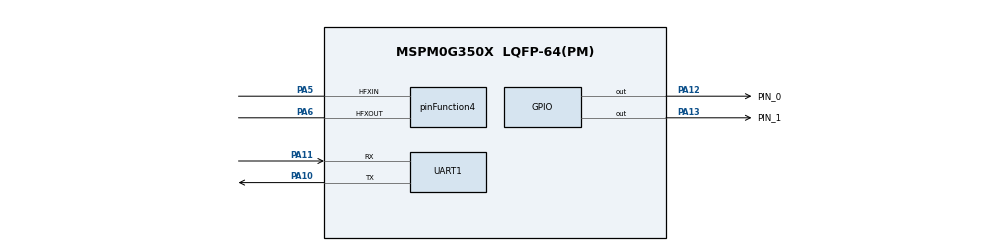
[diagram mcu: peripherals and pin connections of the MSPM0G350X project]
/**
 * @cliArgs --device "MSPM0G350X" --part "Default" --package "LQFP-64(PM)" --product "mspm0_sdk@2.10.00.04"
 * @versions {"tool":"1.26.2+4477"}
 */

/**
 * Import the modules used in this configuration.
 */
const ADC12  = scripting.addModule("/ti/driverlib/ADC12", {}, false);
const ADC121 = ADC12.addInstance();
const GPIO   = scripting.addModule("/ti/driverlib/GPIO", {}, false);
const GPIO1  = GPIO.addInstance();
const SYSCTL = scripting.addModule("/ti/driverlib/SYSCTL");
const TIMER  = scripting.addModule("/ti/driverlib/TIMER", {}, false);
const TIMER1 = TIMER.addInstance();
const UART   = scripting.addModule("/ti/driverlib/UART", {}, false);
const UART1  = UART.addInstance();

/**
 * Write custom configuration values to the imported modules.
 */
const mux4       = system.clockTree["EXHFMUX"];
mux4.inputSelect = "EXHFMUX_XTAL";

const mux8       = system.clockTree["HSCLKMUX"];
mux8.inputSelect = "HSCLKMUX_HFCLK";

const pinFunction4                        = system.clockTree["HFXT"];
pinFunction4.enable                       = true;
pinFunction4.HFCLKMonitor                 = true;
pinFunction4.HFXTStartup                  = 10;
pinFunction4.inputFreq                    = 40;
pinFunction4.peripheral.hfxInPin.$assign  = "PA5";
pinFunction4.peripheral.hfxOutPin.$assign = "PA6";

ADC121.$name                          = "ADC12_0";
ADC121.repeatMode                     = true;
ADC121.trigSrc                        = "DL_ADC12_TRIG_SRC_EVENT";
ADC121.sampClkSrc                     = "DL_ADC12_CLOCK_ULPCLK";
ADC121.subChanID                      = 1;
ADC121.adcMem0chansel                 = "DL_ADC12_INPUT_CHAN_2";
ADC121.adcMem0trig                    = "DL_ADC12_TRIGGER_MODE_TRIGGER_NEXT";
ADC121.sampleTime0                    = "62.5 ns";
ADC121.powerDownMode                  = "DL_ADC12_POWER_DOWN_MODE_MANUAL";
ADC121.configureDMA                   = true;
ADC121.sampCnt                        = 1;
ADC121.enabledDMATriggers             = ["DL_ADC12_DMA_MEM0_RESULT_LOADED"];
ADC121.enabledInterrupts              = ["DL_ADC12_INTERRUPT_DMA_DONE"];
ADC121.peripheral.$assign             = "ADC0";
ADC121.peripheral.adcPin2.$assign     = "PA25";
ADC121.adcPin2Config.$name            = "ti_driverlib_gpio_GPIOPinGeneric0";
ADC121.DMA_CHANNEL.$name              = "DMA_CH0";
ADC121.DMA_CHANNEL.addressMode        = "f2b";
ADC121.DMA_CHANNEL.srcLength          = "HALF_WORD";
ADC121.DMA_CHANNEL.dstLength          = "HALF_WORD";
ADC121.DMA_CHANNEL.peripheral.$assign = "DMA_CH0";

const Board = scripting.addModule("/ti/driverlib/Board", {}, false);

GPIO1.$name                         = "GPIO_GRP_0";
GPIO1.port                          = "PORTA";
GPIO1.associatedPins.create(2);
GPIO1.associatedPins[0].$name       = "PIN_0";
GPIO1.associatedPins[0].pin.$assign = "PA12";
GPIO1.associatedPins[1].$name       = "PIN_1";
GPIO1.associatedPins[1].pin.$assign = "PA13";

SYSCTL.forceDefaultClkConfig = true;
SYSCTL.validateClkStatus     = true;
SYSCTL.clockTreeEn           = true;

TIMER1.$name                       = "SAMPLE_TIMER";
TIMER1.timerMode                   = "PERIODIC";
TIMER1.event1PublisherChannel      = 1;
TIMER1.event1ControllerInterruptEn = ["ZERO_EVENT"];
TIMER1.timerPeriod                 = "400ns";
TIMER1.peripheral.$assign          = "TIMG0";

UART1.$name                       = "UART_0";
UART1.targetBaudRate              = 115200;
UART1.enabledInterrupts           = ["DMA_DONE_RX"];
UART1.enabledDMARXTriggers        = "DL_UART_DMA_INTERRUPT_RX";
UART1.peripheral.rxPin.$assign    = "PA11";
UART1.peripheral.txPin.$assign    = "PA10";
UART1.txPinConfig.$name           = "ti_driverlib_gpio_GPIOPinGeneric1";
UART1.rxPinConfig.$name           = "ti_driverlib_gpio_GPIOPinGeneric2";
UART1.DMA_CHANNEL_RX.$name        = "DMA_CH1";
UART1.DMA_CHANNEL_RX.addressMode  = "f2b";
UART1.DMA_CHANNEL_RX.srcLength    = "BYTE";
UART1.DMA_CHANNEL_RX.dstLength    = "BYTE";
UART1.DMA_CHANNEL_RX.transferMode = "FULL_CH_REPEAT_SINGLE";

/**
 * Pinmux solution for unlocked pins/peripherals. This ensures that minor changes to the automatic solver in a future
 * version of the tool will not impact the pinmux you originally saw.  These lines can be completely deleted in order to
 * re-solve from scratch.
 */
pinFunction4.peripheral.$suggestSolution         = "SYSCTL";
Board.peripheral.$suggestSolution                = "DEBUGSS";
Board.peripheral.swclkPin.$suggestSolution       = "PA20";
Board.peripheral.swdioPin.$suggestSolution       = "PA19";
UART1.peripheral.$suggestSolution                = "UART0";
UART1.DMA_CHANNEL_RX.peripheral.$suggestSolution = "DMA_CH1";
